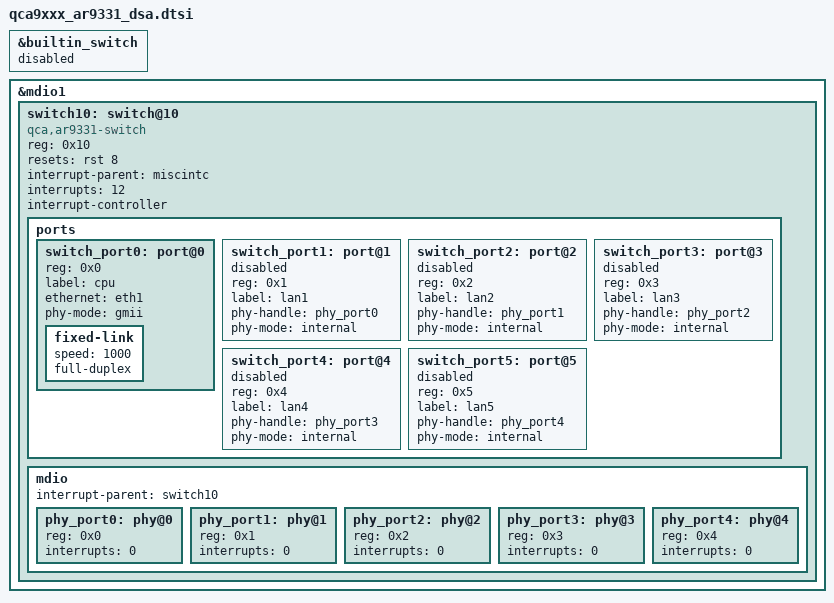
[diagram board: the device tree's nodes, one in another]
&builtin_switch {
	status = "disabled";
};

&mdio1 {
	status = "okay";

	switch10: switch@10 {
		#address-cells = <1>;
		#size-cells = <0>;

		compatible = "qca,ar9331-switch";
		reg = <0x10>;
		resets = <&rst 8>;
		reset-names = "switch";

		interrupt-parent = <&miscintc>;
		interrupts = <12>;

		interrupt-controller;
		#interrupt-cells = <1>;

		ports {
			#address-cells = <1>;
			#size-cells = <0>;

			switch_port0: port@0 {
				reg = <0x0>;
				label = "cpu";
				ethernet = <&eth1>;

				phy-mode = "gmii";

				fixed-link {
					speed = <1000>;
					full-duplex;
				};
			};

			switch_port1: port@1 {
				reg = <0x1>;
				label = "lan1";
				phy-handle = <&phy_port0>;
				phy-mode = "internal";
				status = "disabled";
			};

			switch_port2: port@2 {
				reg = <0x2>;
				label = "lan2";
				phy-handle = <&phy_port1>;
				phy-mode = "internal";
				status = "disabled";
			};

			switch_port3: port@3 {
				reg = <0x3>;
				label = "lan3";
				phy-handle = <&phy_port2>;
				phy-mode = "internal";
				status = "disabled";
			};

			switch_port4: port@4 {
				reg = <0x4>;
				label = "lan4";
				phy-handle = <&phy_port3>;
				phy-mode = "internal";
				status = "disabled";
			};

			switch_port5: port@5 {
				reg = <0x5>;
				label = "lan5";
				phy-handle = <&phy_port4>;
				phy-mode = "internal";
				status = "disabled";
			};

		};

		mdio {
			#address-cells = <1>;
			#size-cells = <0>;
			interrupt-parent = <&switch10>;

			phy_port0: phy@0 {
				reg = <0x0>;
				interrupts = <0>;
			};

			phy_port1: phy@1 {
				reg = <0x1>;
				interrupts = <0>;
			};

			phy_port2: phy@2 {
				reg = <0x2>;
				interrupts = <0>;
			};

			phy_port3: phy@3 {
				reg = <0x3>;
				interrupts = <0>;
			};

			phy_port4: phy@4 {
				reg = <0x4>;
				interrupts = <0>;
			};
		};
	};

};
